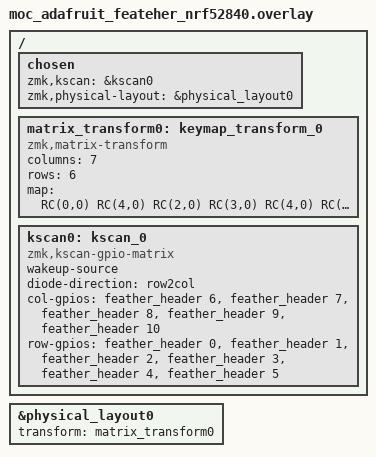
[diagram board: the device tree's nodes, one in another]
/*
 * Copyright (c) 2022 The ZMK Contributors
 *
 * SPDX-License-Identifier: MIT
 */

#include <dt-bindings/zmk/matrix_transform.h>
#include "moc_adafruit_feateher_nrf52840-layouts.dtsi"

&physical_layout0 {
    transform = <&matrix_transform0>;
};

/ {
    chosen {
        zmk,kscan = &kscan0;
        zmk,physical-layout = &physical_layout0;
    };

    matrix_transform0: keymap_transform_0 {
        compatible = "zmk,matrix-transform";
        columns = <7>;
        rows = <6>;
        map = <
    RC(0,0) RC(4,0) RC(2,0) RC(3,0) RC(4,0) RC(5,0) RC(6,0) RC(7,0) RC(8,0) RC(0,1) RC(1,1) RC(2,1)
    RC(1,2) RC(5,0) RC(2,1) RC(3,1) RC(4,1) RC(5,1) RC(6,1) RC(7,1) RC(8,1) RC(n,m) RC(n,m) RC(n,m)
        RC(2,0) RC(6,2) RC(2,2) RC(3,2) RC(4,2) RC(5,2) RC(6,2) RC(7,2) RC(8,2) RC(n,m) RC(n,m)
            RC(3,0) RC(6,3) RC(3,3) RC(4,3) RC(5,3) RC(6,3) RC(7,3) RC(8,3) RC(n,m) RC(n,m)
        >;
    };


    kscan0: kscan_0 {
        compatible = "zmk,kscan-gpio-matrix";
        wakeup-source;

        diode-direction = "row2col";

        col-gpios
            = <&feather_header 6 (GPIO_ACTIVE_HIGH | GPIO_PULL_DOWN)>
            , <&feather_header 7 (GPIO_ACTIVE_HIGH | GPIO_PULL_DOWN)>
            , <&feather_header 8 (GPIO_ACTIVE_HIGH | GPIO_PULL_DOWN)>
            , <&feather_header 9 (GPIO_ACTIVE_HIGH | GPIO_PULL_DOWN)>
            , <&feather_header 10 (GPIO_ACTIVE_HIGH | GPIO_PULL_DOWN)>
            ;

        row-gpios
            = <&feather_header 0 GPIO_ACTIVE_HIGH>
            , <&feather_header 1 GPIO_ACTIVE_HIGH>
            , <&feather_header 2 GPIO_ACTIVE_HIGH>
            , <&feather_header 3 GPIO_ACTIVE_HIGH>
            , <&feather_header 4 GPIO_ACTIVE_HIGH>
            , <&feather_header 5 GPIO_ACTIVE_HIGH>
            ;
    };
};
